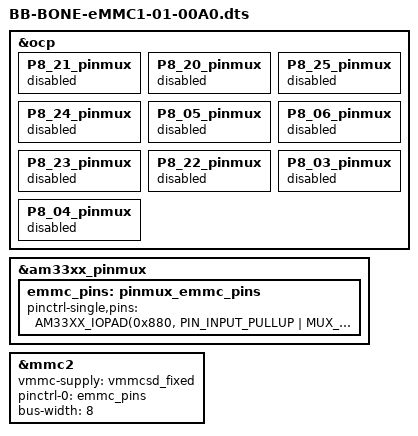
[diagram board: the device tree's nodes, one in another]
/*
 * Copyright (C) 2012 Texas Instruments Incorporated - http://www.ti.com/
 *
 * This program is free software; you can redistribute it and/or modify
 * it under the terms of the GNU General Public License version 2 as
 * published by the Free Software Foundation.
 */

/dts-v1/;
/plugin/;

#include <dt-bindings/gpio/gpio.h>
#include <dt-bindings/pinctrl/am33xx.h>

/ {
	/*
	 * Free up the pins used by the cape from the pinmux helpers.
	 */
	fragment@0 {
		target = <&ocp>;
		__overlay__ {
			P8_21_pinmux { status = "disabled"; };	/* mmc1_clk */
			P8_20_pinmux { status = "disabled"; };	/* mmc1_cmd */
			P8_25_pinmux { status = "disabled"; };	/* mmc1_dat0 */
			P8_24_pinmux { status = "disabled"; };	/* mmc1_dat1 */
			P8_05_pinmux { status = "disabled"; };	/* mmc1_dat2 */
			P8_06_pinmux { status = "disabled"; };	/* mmc1_dat3 */
			P8_23_pinmux { status = "disabled"; };	/* mmc1_dat4 */
			P8_22_pinmux { status = "disabled"; };	/* mmc1_dat5 */
			P8_03_pinmux { status = "disabled"; };	/* mmc1_dat6 */
			P8_04_pinmux { status = "disabled"; };	/* mmc1_dat7 */
		};
	};

	fragment@1 {
		target = <&am33xx_pinmux>;
		__overlay__ {
			emmc_pins: pinmux_emmc_pins {
				pinctrl-single,pins = <
					AM33XX_IOPAD(0x880, PIN_INPUT_PULLUP | MUX_MODE2) /* gpmc_csn1.mmc1_clk */
					AM33XX_IOPAD(0x884, PIN_INPUT_PULLUP | MUX_MODE2) /* gpmc_csn2.mmc1_cmd */
					AM33XX_IOPAD(0x800, PIN_INPUT_PULLUP | MUX_MODE1) /* gpmc_ad0.mmc1_dat0 */
					AM33XX_IOPAD(0x804, PIN_INPUT_PULLUP | MUX_MODE1) /* gpmc_ad1.mmc1_dat1 */
					AM33XX_IOPAD(0x808, PIN_INPUT_PULLUP | MUX_MODE1) /* gpmc_ad2.mmc1_dat2 */
					AM33XX_IOPAD(0x80c, PIN_INPUT_PULLUP | MUX_MODE1) /* gpmc_ad3.mmc1_dat3 */
					AM33XX_IOPAD(0x810, PIN_INPUT_PULLUP | MUX_MODE1) /* gpmc_ad4.mmc1_dat4 */
					AM33XX_IOPAD(0x814, PIN_INPUT_PULLUP | MUX_MODE1) /* gpmc_ad5.mmc1_dat5 */
					AM33XX_IOPAD(0x818, PIN_INPUT_PULLUP | MUX_MODE1) /* gpmc_ad6.mmc1_dat6 */
					AM33XX_IOPAD(0x81c, PIN_INPUT_PULLUP | MUX_MODE1) /* gpmc_ad7.mmc1_dat7 */
				>;
			};
		};
	};

	fragment@2 {
		target = <&mmc2>;
		__overlay__ {
			vmmc-supply = <&vmmcsd_fixed>;
			pinctrl-names = "default";
			pinctrl-0 = <&emmc_pins>;
			bus-width = <8>;
			status = "okay";
		};
	};
};
